# CEC1736_S0_2ZW register map
Vendor: Microchip
Registers are 32-bit, read-write, reset 0x0 unless marked. A register's access mark holds for its fields unless they carry their own. Addresses are absolute, and some are shared; only a register's first bit layout is shown; [hi:lo] are bit positions; {n}, {i} and the like mark numbered series; 'fields as' and 'values as' point back to an identical list.

## TIMER32_1
0x40000CA0 CNT
0x40000CA4 PRLD
0x40000CA8 STS
  [0] EVT_INT — This is the interrupt status that fires when the timer reaches its limit. This is the interrupt status that fires when the timer reaches its limit. This may be level or a self clearing signal cycle pulse, based on the AUTO_RESTART bit in the Timer Control Register. If the timer is set to automatically restart, it will provide a pulse, otherwise a level is provided.(R/WC)
0x40000CAC IEN
  [0] EN — This is the interrupt enable for the status EVENT_INTERRUPT bit in the Timer Status Register.
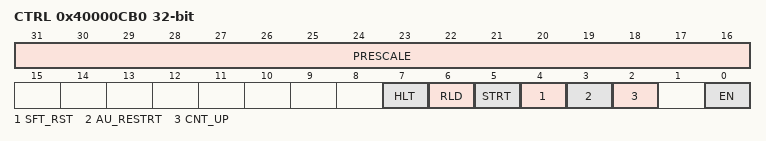
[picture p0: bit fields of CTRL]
0x40000CB0 CTRL
  [31:16] PRESCALE — This is used to divide down the system clock through clock enables to lower the power consumption of the block and allow slow timers. Updating this value during operation may result in erroneous clock enable pulses until the clock divider restarts. The number of clocks per clock enable pulse is (Value + 1); a setting of 0 runs at the full clock speed, while a setting of 1 runs at half speed.
  [7] HLT — This is a halt bit. This will halt the timer as long as it is active. Once the halt is inactive, the timer will start from where it left off. 1=Timer is halted. It stops counting. The clock divider will also be reset. 0=Timer runs normally.
  [6] RLD — This bit reloads the counter without interrupting it operation. This will not function if the timer has already completed (when the START bit in this register is '0'). This is used to periodically prevent the timer from firing when an event occurs. Usage while the timer is off may result in erroneous behaviour.
  [5] STRT — This bit triggers the timer counter. The counter will operate until it hits its terminating condition. This will clear this bit. It should be noted that when operating in restart mode, there is no terminating condition for the counter, so this bit will never clear. Clearing this bit will halt the timer counter.
  [4] SFT_RST — This is a soft reset. This is self clearing 1 cycle after it is written. Firmware does not need to wait before reconfiguring the Basic Timer following soft reset.
  [3] AU_RESTRT — This will select the action taken upon completing a count. 1=The counter will automatically restart the count, using the contents of the Timer Preload Register to load the Timer Count Register. The interrupt will be set in edge mode 0=The counter will simply enter a done state and wait for further control inputs. The interrupt will be set in level mode.
  [2] CNT_UP — This selects the counter direction. When the counter in incrementing the counter will saturate and trigger the event when it reaches all F's. When the counter is decrementing the counter will saturate when it reaches 0h. 1=The counter will increment; 0=The counter will decrement
  [0] EN — This enables the block for operation. 1=This block will function normally; 0=This block will gate its clock and go into its lowest power state

## CCT
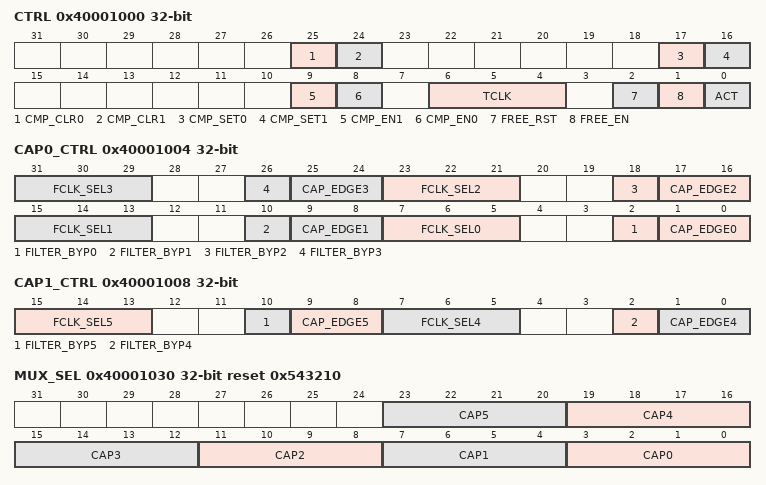
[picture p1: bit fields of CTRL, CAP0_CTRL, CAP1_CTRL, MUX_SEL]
0x40001000 CTRL
  [25] CMP_CLR0 — When read, returns the current value off the Compare Timer Output 0 state.
  [24] CMP_CLR1 — When read, returns the current value off the Compare Timer Output 1 state.
  [17] CMP_SET0 — When read, returns the current value off the Compare Timer Output 0 state.
  [16] CMP_SET1 — When read, returns the current value off the Compare Timer Output 1 state.
  [9] CMP_EN1 — Compare Enable for Compare 1 Register.
  [8] CMP_EN0 — Compare Enable for Compare 0 Register.
  [6:4] TCLK — This 3-bit field sets the clock source for the Free-Running Counter.
  [2] FREE_RST — Free Running Timer Reset. This bit stops the timer and resets the internal counter to 0000_0000h.
  [1] FREE_EN — Free-Running Timer Enable. This bit is used to start and stop the free running timer.
  [0] ACT — This bit is used to start the capture and compare timer running and power it down.
0x40001004 CAP0_CTRL
  [8n+7:8n+5] FCLK_SEL{n} (n=0..3) — This 3-bit field sets the clock source for the input filter for Capture Register {n}.
    0=DIV_1 (Divide by 1 (48 MHz)); 1=DIV_2 (Divide by 2 (24 MHz)); 2=DIV_4 (Divide by 4 (12 MHz)); 3=DIV_8 (Divide by 8 (6 MHz)); 4=DIV_16 (Divide by 16 (3 MHz)); 5=DIV_32 (Divide by 32 (1.5 MHz)); 6=DIV_64 (Divide by 64 (750 KHz)); 7=DIV_128 (Divide by 128 (375 KHz))
  [8n+2] FILTER_BYP{n} (n=0..3) — This bit enables bypassing the input noise filter for Capture Register {n}, so that the input signal goes directly into the timer.
  [8n+1:8n] CAP_EDGE{n} (n=0..3) — This field selects the edge type that triggers the capture of the Free Running Counter into Capture Register {n}.
    0=FALLING (Capture on falling edge); 1=RISING (Capture on rising edge); 2=BOTH (Capture on both falling and rising edges); 3=DISABLED (Capture event disabled)
0x40001008 CAP1_CTRL
  [15:13] FCLK_SEL5 — This 3-bit field sets the clock source for the input filter for Capture Register 5.
    values as CAP0_CTRL.FCLK_SEL0
  [10] FILTER_BYP5 — This bit enables bypassing the input noise filter for Capture Register 5, so that the input signal goes directly into the timer.
  [9:8] CAP_EDGE5 — This field selects the edge type that triggers the capture of the Free Running Counter into Capture Register 5.
    values as CAP0_CTRL.CAP_EDGE0
  [7:5] FCLK_SEL4 — This 3-bit field sets the clock source for the input filter for Capture Register 4.
    values as CAP0_CTRL.FCLK_SEL0
  [2] FILTER_BYP4 — This bit enables bypassing the input noise filter for Capture Register 4, so that the input signal goes directly into the timer.
  [1:0] CAP_EDGE4 — This field selects the edge type that triggers the capture of the Free Running Counter into Capture Register 4.
    values as CAP0_CTRL.CAP_EDGE0
0x4000100C FREE_RUN
  [31:0] TMR — This register contains the current value of the Free Running Timer.
{0x40001010+4i} CAP{i} (i=0..5)
  [31:0] CAP_{i} — This register saves the value copied from the Free Running timer on a programmed edge of ICT{i}.
0x40001028 COMP0
  [31:0] COMP_0 — A COMPARE 0 interrupt is generated when this register matches the value in the Free Running Timer.
0x4000102C COMP1
  [31:0] COMP_1 — A COMPARE 1 interrupt is generated when this register matches the value in the Free Running Timer.
0x40001030 MUX_SEL reset 0x543210
  [4n+3:4n] CAP{n} (n=0..5) — Mux Select for Capture {n} register.
